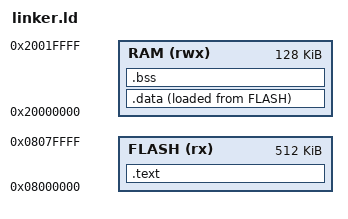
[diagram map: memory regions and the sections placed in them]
ENTRY(_start)

MEMORY
{
    FLASH (rx)  : ORIGIN = 0x08000000, LENGTH = 512K
    RAM   (rwx) : ORIGIN = 0x20000000, LENGTH = 128K
}

SECTIONS
{
    .text :
    {
        KEEP(*(.text.startup))
        *(.text*)
        *(.rodata*)
    } > FLASH

    .data :
    {
        __data_start__ = .;
        *(.data*)
        __data_end__ = .;
    } > RAM AT > FLASH

    __data_load__ = LOADADDR(.data);

    .bss :
    {
        . = ALIGN(4);
        __bss_start__ = .;
        *(.bss*)
        *(COMMON)
        . = ALIGN(4);
        __bss_end__ = .;
    } > RAM

    . = ALIGN(8);

    _end = .;
    _stack_top = 0x2000F000;
}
